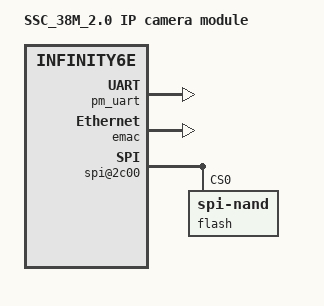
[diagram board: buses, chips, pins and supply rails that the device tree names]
// SPDX-License-Identifier: GPL-2.0-or-later
/*
 * Copyright (c) 2026 Petr Kracik <petrkr@petrkr.net>
 */

/dts-v1/;

#include "mstar-infinity6e-ssc338q.dtsi"

/ {
	model = "SSC_38M_2.0 IP camera module";
	compatible = "sstar,ssc38m-v2", "mstar,infinity6e";

	aliases {
		serial0 = &pm_uart;
	};

	chosen {
		stdout-path = "serial0:115200n8";
	};
};

&pm_uart {
	status = "okay";
};

&gpio {
	status = "okay";
};

&emac {
	pinctrl-names = "default";
	pinctrl-0 = <&eth_default>;
	status = "okay";
};

&riu {
	spi@2c00 {
		status = "okay";

		flash@0 {
			compatible = "spi-nand";
			reg = <0>;
			spi-rx-bus-width = <1>;
			spi-tx-bus-width = <1>;
		};
	};
};
